VERSION ""

NS_ :

BS_:

BU_: XXX

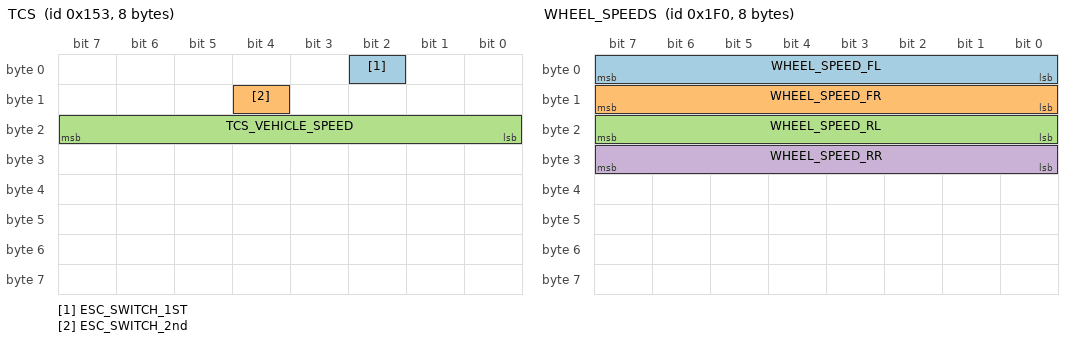
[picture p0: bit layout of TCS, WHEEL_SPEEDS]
BO_ 339 TCS: 8 XXX
 SG_ ESC_SWITCH_1ST : 2|1@1+ (1,0) [0|3] "" XXX
 SG_ ESC_SWITCH_2nd : 12|1@0+ (1,0) [0|3] "" XXX
 SG_ TCS_VEHICLE_SPEED : 23|8@0+ (1,0) [0|255] "km/h" XXX

BO_ 496 WHEEL_SPEEDS: 8 XXX
 SG_ WHEEL_SPEED_FL : 7|8@0+ (1,0) [0|255] "km/h" XXX
 SG_ WHEEL_SPEED_FR : 15|8@0+ (1,0) [0|255] "km/h" XXX
 SG_ WHEEL_SPEED_RL : 23|8@0+ (1,0) [0|255] "km/h" XXX
 SG_ WHEEL_SPEED_RR : 31|8@0+ (1,0) [0|255] "km/h" XXX

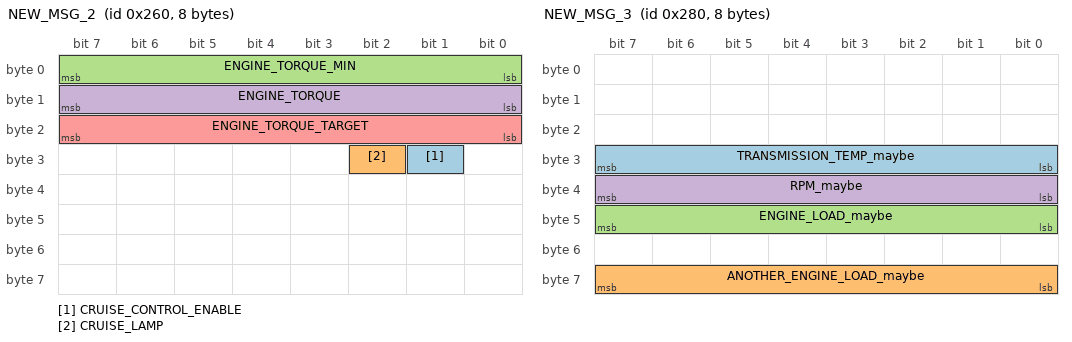
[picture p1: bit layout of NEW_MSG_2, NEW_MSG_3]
BO_ 608 NEW_MSG_2: 8 XXX
 SG_ CRUISE_CONTROL_ENABLE : 25|1@0+ (1,0) [0|1] "" XXX
 SG_ CRUISE_LAMP : 26|1@0+ (1,0) [0|1] "" XXX
 SG_ ENGINE_TORQUE_MIN : 0|8@1+ (1,0) [0|255] "" XXX
 SG_ ENGINE_TORQUE : 8|8@1+ (1,0) [0|255] "" XXX
 SG_ ENGINE_TORQUE_TARGET : 23|8@0+ (1,0) [0|255] "Also follows the first half of the throttle" XXX

BO_ 640 NEW_MSG_3: 8 XXX
 SG_ TRANSMISSION_TEMP_maybe : 31|8@0+ (1,0) [0|255] "" XXX
 SG_ ANOTHER_ENGINE_LOAD_maybe : 63|8@0+ (1,0) [0|255] "" XXX
 SG_ ENGINE_LOAD_maybe : 47|8@0+ (1,0) [0|255] "" XXX
 SG_ RPM_maybe : 39|8@0+ (20,0) [0|3500] "" XXX

BO_ 672 NEW_MSG_4: 8 XXX
 SG_ NEW_SIGNAL_1 : 16|2@1+ (1,0) [0|3] "" XXX
 SG_ NEW_SIGNAL_2 : 32|5@1+ (1,0) [0|255] "" XXX

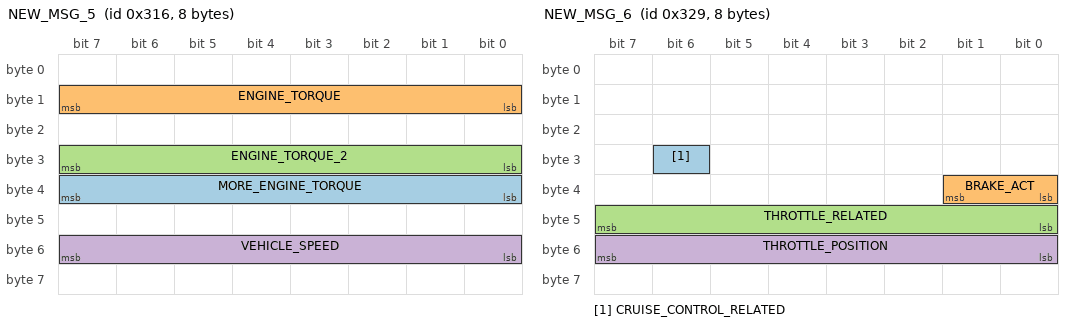
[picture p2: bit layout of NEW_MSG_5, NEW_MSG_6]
BO_ 790 NEW_MSG_5: 8 XXX
 SG_ MORE_ENGINE_TORQUE : 39|8@0+ (1,0) [0|255] "%" XXX
 SG_ ENGINE_TORQUE : 15|8@0+ (1,0) [0|255] "%" XXX
 SG_ ENGINE_TORQUE_2 : 31|8@0+ (1,0) [0|255] "%" XXX
 SG_ VEHICLE_SPEED : 55|8@0+ (1,0) [0|255] "km/h" XXX

BO_ 809 NEW_MSG_6: 8 XXX
 SG_ CRUISE_CONTROL_RELATED : 30|1@0+ (1,0) [0|3] "" XXX
 SG_ BRAKE_ACT : 33|2@0+ (1,0) [0|255] "" XXX
 SG_ THROTTLE_RELATED : 47|8@0+ (1,0) [0|255] "" XXX
 SG_ THROTTLE_POSITION : 55|8@0+ (1,0) [0|255] "" XXX

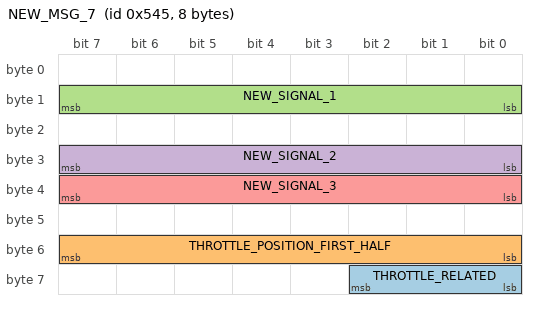
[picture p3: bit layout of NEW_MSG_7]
BO_ 1349 NEW_MSG_7: 8 XXX
 SG_ THROTTLE_RELATED : 56|3@1+ (1,0) [0|7] "" XXX
 SG_ THROTTLE_POSITION_FIRST_HALF : 55|8@0+ (1,0) [0|255] "" XXX
 SG_ NEW_SIGNAL_1 : 15|8@0+ (1,0) [0|255] "" XXX
 SG_ NEW_SIGNAL_2 : 31|8@0+ (1,0) [0|255] "" XXX
 SG_ NEW_SIGNAL_3 : 39|8@0+ (1,0) [0|255] "" XXX

BO_ 1087 NEW_MSG_1: 8 XXX
 SG_ MAYBE_TORQUE : 55|8@0+ (1,0) [0|255] "" XXX
 SG_ COUNTER_CHECKSUM_MAYBE : 47|8@0+ (1,0) [0|255] "" XXX

BO_ 1088 NEW_MSG_8: 8 XXX

CM_ SG_ 608 CRUISE_LAMP "This is the enabled, disabled status";
CM_ SG_ 608 ENGINE_TORQUE_TARGET "This also closely corresponds to the first half of the throttle";
CM_ SG_ 640 RPM_maybe "This scaling may be incorrect";
CM_ SG_ 790 ENGINE_TORQUE_2 "This could also be rpm";
CM_ SG_ 1087 COUNTER_CHECKSUM_MAYBE "It is kind of related to speed";
